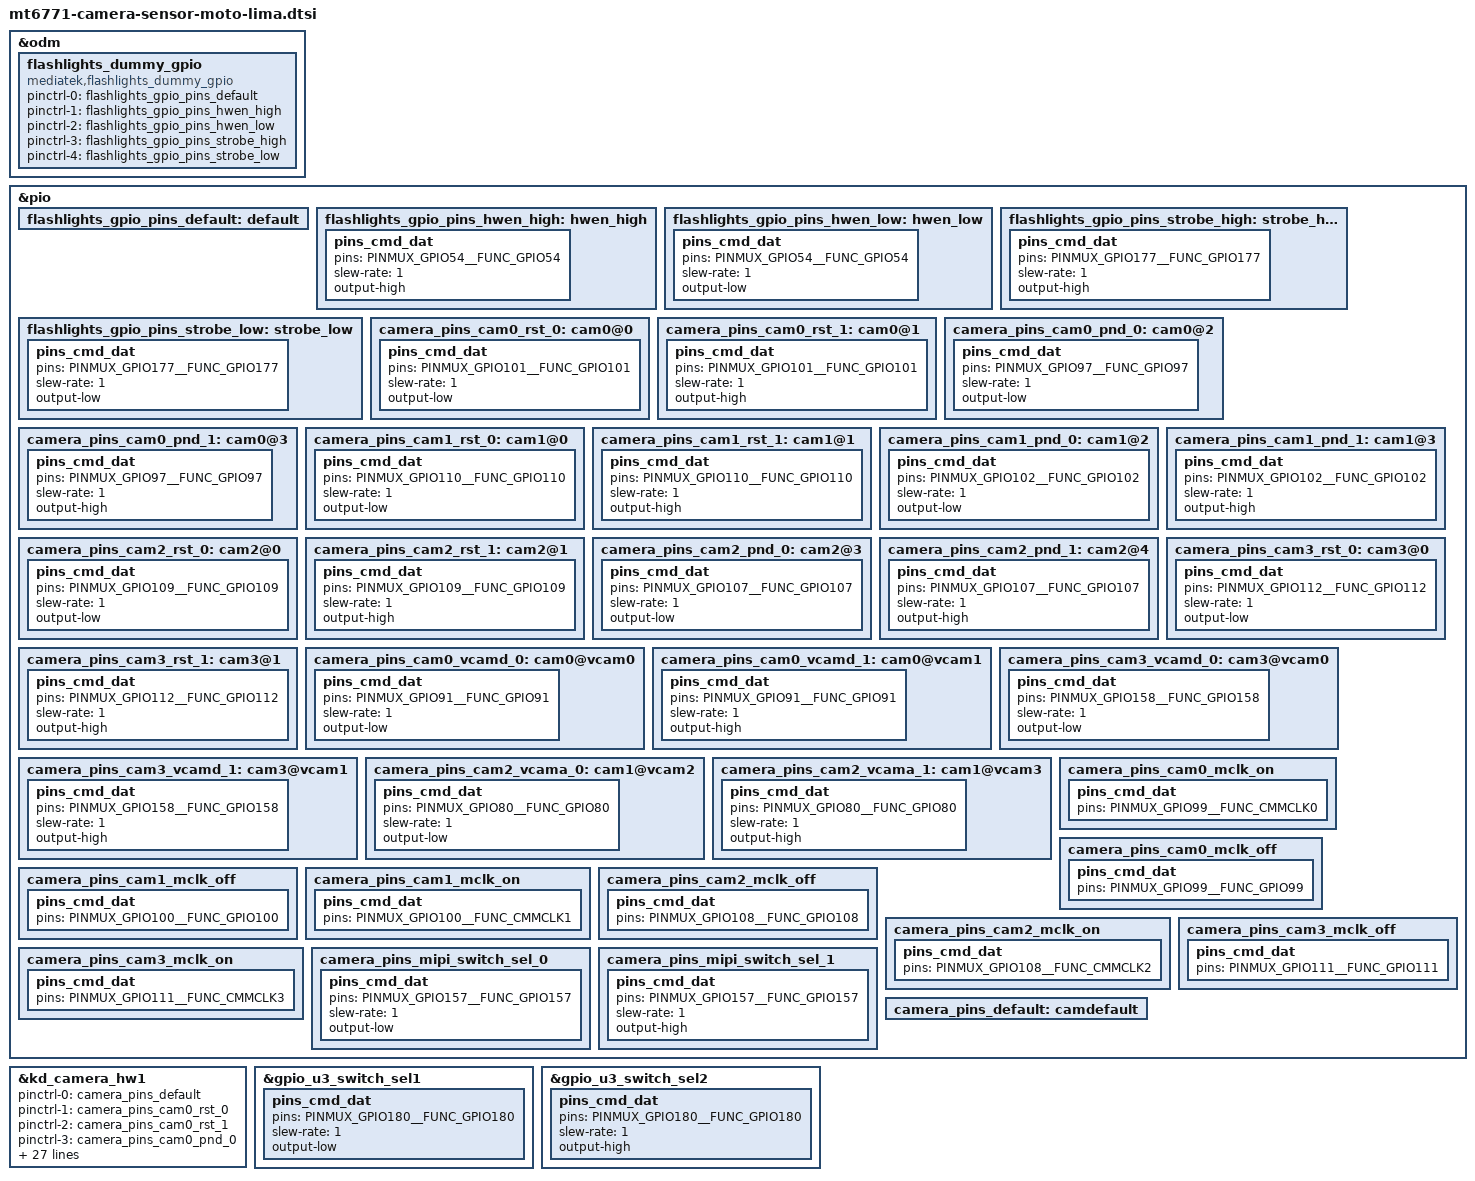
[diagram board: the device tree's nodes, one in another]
/* Copyright (c) 2019, Motorola Mobility Inc. All rights reserved.
 *
 * This program is free software; you can redistribute it and/or modify
 * it under the terms of the GNU General Public License version 2 and
 * only version 2 as published by the Free Software Foundation.
 *
 * This program is distributed in the hope that it will be useful,
 * but WITHOUT ANY WARRANTY; without even the implied warranty of
 * MERCHANTABILITY or FITNESS FOR A PARTICULAR PURPOSE.  See the
 * GNU General Public License for more details.
 */

&odm {
	flashlights_dummy_gpio: flashlights_dummy_gpio {
	compatible = "mediatek,flashlights_dummy_gpio";
	};
};

&pio {
	flashlights_gpio_pins_default: default {
	};
	flashlights_gpio_pins_hwen_high: hwen_high {
		pins_cmd_dat {
			pins = <PINMUX_GPIO54__FUNC_GPIO54>;
			slew-rate = <1>;
			output-high;
		};
	};
	flashlights_gpio_pins_hwen_low: hwen_low {
		pins_cmd_dat {
			pins = <PINMUX_GPIO54__FUNC_GPIO54>;
			slew-rate = <1>;
			output-low;
		};
	};
	flashlights_gpio_pins_strobe_high: strobe_high {
		pins_cmd_dat {
			pins = <PINMUX_GPIO177__FUNC_GPIO177>;
			slew-rate = <1>;
			output-high;
		};
	};
	flashlights_gpio_pins_strobe_low: strobe_low {
		pins_cmd_dat {
			pins = <PINMUX_GPIO177__FUNC_GPIO177>;
			slew-rate = <1>;
			output-low;
		};
	};
};
&flashlights_dummy_gpio {
	pinctrl-names = "default", "hwen_high", "hwen_low", "strobe_high", "strobe_low";
	pinctrl-0 = <&flashlights_gpio_pins_default>;
	pinctrl-1 = <&flashlights_gpio_pins_hwen_high>;
	pinctrl-2 = <&flashlights_gpio_pins_hwen_low>;
	pinctrl-3 = <&flashlights_gpio_pins_strobe_high>;
	pinctrl-4 = <&flashlights_gpio_pins_strobe_low>;
	status = "okay";
};

/* CAMERA GPIO standardization */
&pio {
	camera_pins_cam0_rst_0: cam0@0 {
		pins_cmd_dat {
			pins = <PINMUX_GPIO101__FUNC_GPIO101>;
			slew-rate = <1>; /*direction 0:in, 1:out*/
			output-low;/*direction out used only. output_low or high*/
		};
	};
	camera_pins_cam0_rst_1: cam0@1 {
		pins_cmd_dat {
			pins = <PINMUX_GPIO101__FUNC_GPIO101>;
			slew-rate = <1>;
			output-high;
		};
	};
	camera_pins_cam0_pnd_0: cam0@2 {
		pins_cmd_dat {
			pins = <PINMUX_GPIO97__FUNC_GPIO97>;
			slew-rate = <1>;
			output-low;
		};
	};
	camera_pins_cam0_pnd_1: cam0@3 {
		pins_cmd_dat {
			pins = <PINMUX_GPIO97__FUNC_GPIO97>;
			slew-rate = <1>;
			output-high;
		};
	};
	camera_pins_cam1_rst_0: cam1@0 {
		pins_cmd_dat {
			pins = <PINMUX_GPIO110__FUNC_GPIO110>;
			slew-rate = <1>; /*direction 0:in, 1:out*/
			output-low;/*direction out used only. output_low or high*/
		};
	};
	camera_pins_cam1_rst_1: cam1@1 {
		pins_cmd_dat {
			pins = <PINMUX_GPIO110__FUNC_GPIO110>;
			slew-rate = <1>;
			output-high;
		};
	};
	camera_pins_cam1_pnd_0: cam1@2 {
		pins_cmd_dat {
			pins = <PINMUX_GPIO102__FUNC_GPIO102>;
			slew-rate = <1>;
			output-low;
		};
	};
	camera_pins_cam1_pnd_1: cam1@3 {
		pins_cmd_dat {
			pins = <PINMUX_GPIO102__FUNC_GPIO102>;
			slew-rate = <1>;
			output-high;
		};
	};
	camera_pins_cam2_rst_0: cam2@0 {
		pins_cmd_dat {
			pins = <PINMUX_GPIO109__FUNC_GPIO109>;
			slew-rate = <1>;
			output-low;
		};
	};
	camera_pins_cam2_rst_1: cam2@1 {
		pins_cmd_dat {
			pins = <PINMUX_GPIO109__FUNC_GPIO109>;
			slew-rate = <1>;
			output-high;
		};
	};
	camera_pins_cam2_pnd_0: cam2@3 {
		pins_cmd_dat {
			pins = <PINMUX_GPIO107__FUNC_GPIO107>;
			slew-rate = <1>;
			output-low;
		};
	};
	camera_pins_cam2_pnd_1: cam2@4 {
		pins_cmd_dat {
			pins = <PINMUX_GPIO107__FUNC_GPIO107>;
			slew-rate = <1>;
			output-high;
		};
	};
	camera_pins_cam3_rst_0: cam3@0 {
		pins_cmd_dat {
			pins = <PINMUX_GPIO112__FUNC_GPIO112>;
			slew-rate = <1>; /*direction 0:in, 1:out*/
			output-low;/*direction out used only. output_low or high*/
		};
	};
	camera_pins_cam3_rst_1: cam3@1 {
		pins_cmd_dat {
			pins = <PINMUX_GPIO112__FUNC_GPIO112>;
			slew-rate = <1>;
			output-high;
		};
	};
	camera_pins_cam0_vcamd_0: cam0@vcam0 {
		pins_cmd_dat {
			pins = <PINMUX_GPIO91__FUNC_GPIO91>;
			slew-rate = <1>;
			output-low;
		};
	};
	camera_pins_cam0_vcamd_1: cam0@vcam1 {
		pins_cmd_dat {
			pins = <PINMUX_GPIO91__FUNC_GPIO91>;
			slew-rate = <1>;
			output-high;
		};
	};
	camera_pins_cam3_vcamd_0: cam3@vcam0 {
		pins_cmd_dat {
			pins = <PINMUX_GPIO158__FUNC_GPIO158>;
			slew-rate = <1>;
			output-low;
		};
	};
	camera_pins_cam3_vcamd_1: cam3@vcam1 {
		pins_cmd_dat {
			pins = <PINMUX_GPIO158__FUNC_GPIO158>;
			slew-rate = <1>;
			output-high;
		};
	};
	camera_pins_cam2_vcama_0: cam1@vcam2 {
		pins_cmd_dat {
			pins = <PINMUX_GPIO80__FUNC_GPIO80>;
			slew-rate = <1>;
			output-low;
		};
	};
	camera_pins_cam2_vcama_1: cam1@vcam3 {
		pins_cmd_dat {
			pins = <PINMUX_GPIO80__FUNC_GPIO80>;
			slew-rate = <1>;
			output-high;
		};
	};
	camera_pins_cam0_mclk_on: camera_pins_cam0_mclk_on {
		pins_cmd_dat {
			pins = <PINMUX_GPIO99__FUNC_CMMCLK0>;
		};
	};
	camera_pins_cam0_mclk_off: camera_pins_cam0_mclk_off {
		pins_cmd_dat {
			pins = <PINMUX_GPIO99__FUNC_GPIO99>;
		};
	};
	camera_pins_cam1_mclk_off: camera_pins_cam1_mclk_off {
		pins_cmd_dat {
			pins = <PINMUX_GPIO100__FUNC_GPIO100>;
		};
	};
	camera_pins_cam1_mclk_on: camera_pins_cam1_mclk_on {
		pins_cmd_dat {
			pins = <PINMUX_GPIO100__FUNC_CMMCLK1>;
		};
	};
	camera_pins_cam2_mclk_off: camera_pins_cam2_mclk_off {
		pins_cmd_dat {
			pins = <PINMUX_GPIO108__FUNC_GPIO108>;
		};
	};
	camera_pins_cam2_mclk_on: camera_pins_cam2_mclk_on {
		pins_cmd_dat {
			pins = <PINMUX_GPIO108__FUNC_CMMCLK2>;
		};
	};
	camera_pins_cam3_mclk_off: camera_pins_cam3_mclk_off {
		pins_cmd_dat {
			pins = <PINMUX_GPIO111__FUNC_GPIO111>;
		};
	};
	camera_pins_cam3_mclk_on: camera_pins_cam3_mclk_on {
		pins_cmd_dat {
			pins = <PINMUX_GPIO111__FUNC_CMMCLK3>;
		};
	};
	camera_pins_mipi_switch_sel_0: camera_pins_mipi_switch_sel_0 {
		pins_cmd_dat {
			pins = <PINMUX_GPIO157__FUNC_GPIO157>;
			slew-rate = <1>;
			output-low;
		};
	};
	camera_pins_mipi_switch_sel_1: camera_pins_mipi_switch_sel_1 {
		pins_cmd_dat {
			pins = <PINMUX_GPIO157__FUNC_GPIO157>;
                        slew-rate = <1>;
                        output-high;
		};
	};
	camera_pins_default: camdefault {
	};
};

&kd_camera_hw1 {
	pinctrl-names = "default",
			"cam0_rst0", "cam0_rst1",
			"cam0_pnd0", "cam0_pnd1",
			"cam1_rst0", "cam1_rst1",
			"cam1_pnd0", "cam1_pnd1",
			"cam2_rst0", "cam2_rst1",
			"cam2_pnd0", "cam2_pnd1",
			"cam3_rst0", "cam3_rst1",
			"cam_ldo_vcamd_0", "cam_ldo_vcamd_1",
			"cam_ldo_sub2_vcamd_0", "cam_ldo_sub2_vcamd_1",
			"cam_ldo_main2_vcama_0", "cam_ldo_main2_vcama_1",
			"cam0_mclk_off", "cam0_mclk_on",
			"cam1_mclk_off", "cam1_mclk_on",
			"cam2_mclk_off", "cam2_mclk_on",
			"cam3_mclk_off", "cam3_mclk_on",
			"cam_mipi_switch_sel_0", "cam_mipi_switch_sel_1";
	pinctrl-0 = <&camera_pins_default>;
	pinctrl-1 = <&camera_pins_cam0_rst_0>;
	pinctrl-2 = <&camera_pins_cam0_rst_1>;
	pinctrl-3 = <&camera_pins_cam0_pnd_0>;
	pinctrl-4 = <&camera_pins_cam0_pnd_1>;
	pinctrl-5 = <&camera_pins_cam1_rst_0>;
	pinctrl-6 = <&camera_pins_cam1_rst_1>;
	pinctrl-7 = <&camera_pins_cam1_pnd_0>;
	pinctrl-8 = <&camera_pins_cam1_pnd_1>;
	pinctrl-9 = <&camera_pins_cam2_rst_0>;
	pinctrl-10 = <&camera_pins_cam2_rst_1>;
	pinctrl-11 = <&camera_pins_cam2_pnd_0>;
	pinctrl-12 = <&camera_pins_cam2_pnd_1>;
	pinctrl-13 = <&camera_pins_cam3_rst_0>;
	pinctrl-14 = <&camera_pins_cam3_rst_1>;
	pinctrl-15 = <&camera_pins_cam0_vcamd_0>;
	pinctrl-16 = <&camera_pins_cam0_vcamd_1>;
	pinctrl-17 = <&camera_pins_cam3_vcamd_0>;
	pinctrl-18 = <&camera_pins_cam3_vcamd_1>;
	pinctrl-19 = <&camera_pins_cam2_vcama_0>;
	pinctrl-20 = <&camera_pins_cam2_vcama_1>;
	pinctrl-21 = <&camera_pins_cam0_mclk_off>;
	pinctrl-22 = <&camera_pins_cam0_mclk_on>;
	pinctrl-23 = <&camera_pins_cam1_mclk_off>;
	pinctrl-24 = <&camera_pins_cam1_mclk_on>;
	pinctrl-25 = <&camera_pins_cam2_mclk_off>;
	pinctrl-26 = <&camera_pins_cam2_mclk_on>;
	pinctrl-27 = <&camera_pins_cam3_mclk_off>;
	pinctrl-28 = <&camera_pins_cam3_mclk_on>;
	pinctrl-29 = <&camera_pins_mipi_switch_sel_0>;
	pinctrl-30 = <&camera_pins_mipi_switch_sel_1>;
	status = "okay";
};

/* USB TYPEC GPIO start */
&gpio_u3_switch_sel1 {
	pins_cmd_dat {
		pins = <PINMUX_GPIO180__FUNC_GPIO180>;
		slew-rate = <1>;
		output-low;
	};
};

&gpio_u3_switch_sel2 {
	pins_cmd_dat {
		pins = <PINMUX_GPIO180__FUNC_GPIO180>;
		slew-rate = <1>;
		output-high;
	};
};

